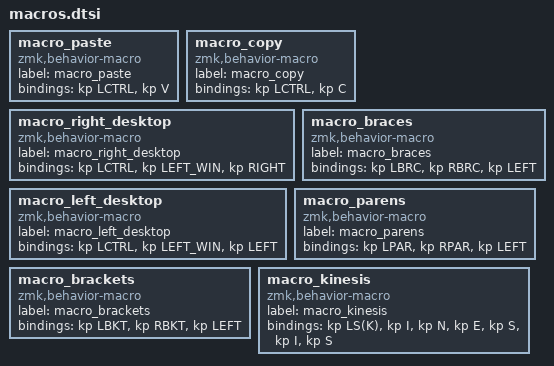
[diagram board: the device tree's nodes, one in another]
macro_paste: macro_paste{
compatible = "zmk,behavior-macro";
label = "macro_paste";
#binding-cells = <0>;
bindings = <&kp LCTRL &kp V>;
};
macro_copy: macro_copy{
compatible = "zmk,behavior-macro";
label = "macro_copy";
#binding-cells = <0>;
bindings = <&kp LCTRL &kp C>;
};
macro_right_desktop: macro_right_desktop{
compatible = "zmk,behavior-macro";
label = "macro_right_desktop";
#binding-cells = <0>;
bindings = <&kp LCTRL &kp LEFT_WIN &kp RIGHT>;
};
macro_left_desktop: macro_left_desktop{
compatible = "zmk,behavior-macro";
label = "macro_left_desktop";
#binding-cells = <0>;
bindings = <&kp LCTRL &kp LEFT_WIN &kp LEFT>;
};
macro_braces: macro_braces{
compatible = "zmk,behavior-macro";
label = "macro_braces";
#binding-cells = <0>;
bindings = <&kp LBRC>, <&kp RBRC>, <&kp LEFT>;
};
macro_parens: macro_parens{
compatible = "zmk,behavior-macro";
label = "macro_parens";
#binding-cells = <0>;
bindings = <&kp LPAR>, <&kp RPAR>, <&kp LEFT>;
};
macro_brackets: macro_brackets{
compatible = "zmk,behavior-macro";
label = "macro_brackets";
#binding-cells = <0>;
bindings = <&kp LBKT>, <&kp RBKT>, <&kp LEFT>;
};
macro_kinesis: macro_kinesis{
compatible = "zmk,behavior-macro";
label = "macro_kinesis";
#binding-cells = <0>;
bindings = <&kp LS(K)>, <&kp I>, <&kp N>, <&kp E>, <&kp S>, <&kp I>, <&kp S>;
};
